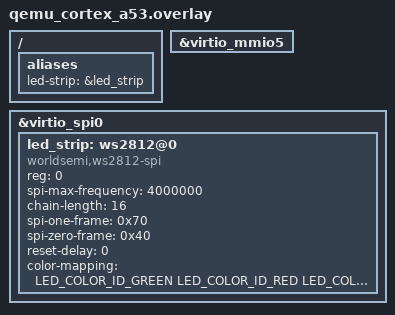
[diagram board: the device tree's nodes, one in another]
/*
 * Copyright (c) 2026
 * SPDX-License-Identifier: Apache-2.0
 *
 * zephyr-module/apps/led_strip: WS2812 on virtio-spi CS0. Self-contained —
 * does not compose with the virtio-spi snippet (that one puts a JEDEC NOR on
 * CS0). The guest encodes each WS2812 bit as an 8-bit SPI symbol; the page
 * decodes the bitstream and paints the strip.
 *
 * spi-max-frequency is binding-required but does not pace aemu. reset-delay
 * is zeroed: there is no silicon latch here, and a non-zero value used to
 * cost a full QEMU tick (~10 ms) on top of the chase period.
 */

#include <zephyr/dt-bindings/led/led.h>

&virtio_mmio5 {
	status = "okay";
};

&virtio_spi0 {
	status = "okay";

	led_strip: ws2812@0 {
		compatible = "worldsemi,ws2812-spi";
		reg = <0>;
		/* Binding-required; ignored for wall-clock pacing in the browser. */
		spi-max-frequency = <4000000>;
		chain-length = <16>;
		/* Common 8-bit symbol pair used by many Zephyr board overlays. */
		spi-one-frame = <0x70>;
		spi-zero-frame = <0x40>;
		/* No latch wait in aemu — avoids a tick-ceiled k_usleep tax. */
		reset-delay = <0>;
		color-mapping = <LED_COLOR_ID_GREEN
				 LED_COLOR_ID_RED
				 LED_COLOR_ID_BLUE>;
		status = "okay";
	};
};

/ {
	aliases {
		led-strip = &led_strip;
	};
};
